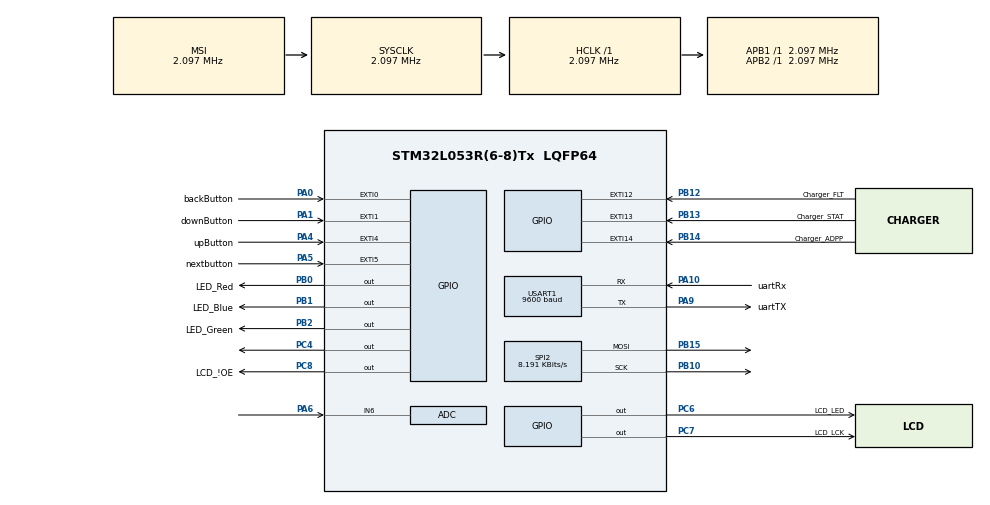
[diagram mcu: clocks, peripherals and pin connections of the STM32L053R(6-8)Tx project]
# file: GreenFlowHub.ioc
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ADC.ClockPrescaler=ADC_CLOCK_SYNC_PCLK_DIV4
ADC.ContinuousConvMode=ENABLE
ADC.Overrun=ADC_OVR_DATA_OVERWRITTEN
ADC.Resolution=ADC_RESOLUTION_12B
ADC.SamplingTime=ADC_SAMPLETIME_39CYCLES_5
Mcu.Family=STM32L0
Mcu.Name=STM32L053R(6-8)Tx
Mcu.Package=LQFP64
NVIC.EXTI0_1_IRQn=true\:0\:0\:false\:false\:true
NVIC.EXTI4_15_IRQn=true\:0\:0\:false\:false\:true
NVIC.USART1_IRQn=true\:0\:0\:false\:false\:true
PA0.GPIO_Label=backButton
PA0.GPIO_ModeDefaultEXTI=GPIO_MODE_IT_RISING
PA0.GPIO_PuPd=GPIO_PULLDOWN
PA0.Signal=GPXTI0
PA1.GPIO_Label=downButton
PA1.GPIO_PuPd=GPIO_PULLDOWN
PA1.Signal=GPXTI1
PA10.GPIO_Label=uartRx
PA10.GPIO_Speed=GPIO_SPEED_FREQ_VERY_HIGH
PA10.Mode=Asynchronous
PA10.Signal=USART1_RX
PA4.GPIO_Label=upButton
PA4.GPIO_PuPd=GPIO_PULLDOWN
PA4.Signal=GPXTI4
PA5.GPIO_Label=nextbutton
PA5.GPIO_PuPd=GPIO_PULLDOWN
PA5.Signal=GPXTI5
PA6.Mode=IN6
PA6.Signal=ADC_IN6
PA9.GPIO_Label=uartTX
PA9.GPIO_Speed=GPIO_SPEED_FREQ_VERY_HIGH
PA9.Mode=Asynchronous
PA9.Signal=USART1_TX
PB0.GPIO_Label=LED_Red
PB0.Signal=GPIO_Output
PB1.GPIO_Label=LED_Blue
PB1.Signal=GPIO_Output
PB10.Mode=TX_Only_Simplex_Unidirect_Master
PB10.Signal=SPI2_SCK
PB12.GPIO_Label=Charger_FLT
PB12.GPIO_PuPd=GPIO_PULLDOWN
PB12.Signal=GPXTI12
PB13.GPIO_Label=Charger_STAT
PB13.GPIO_PuPd=GPIO_PULLDOWN
PB13.Signal=GPXTI13
PB14.GPIO_Label=Charger_ADPP
PB14.GPIO_PuPd=GPIO_PULLDOWN
PB14.Signal=GPXTI14
PB15.Mode=TX_Only_Simplex_Unidirect_Master
PB15.Signal=SPI2_MOSI
PB2.GPIO_Label=LED_Green
PB2.Signal=GPIO_Output
PC4.Signal=GPIO_Output
PC6.GPIO_Label=LCD_LED
PC6.GPIO_PuPd=GPIO_PULLDOWN
PC6.Signal=GPIO_Output
PC7.GPIO_Label=LCD_LCK
PC7.GPIO_PuPd=GPIO_NOPULL
PC7.Signal=GPIO_Output
PC8.GPIO_Label=LCD_\!OE
PC8.GPIO_PuPd=GPIO_PULLDOWN
PC8.Signal=GPIO_Output
ProjectManager.HeapSize=0x200
ProjectManager.StackSize=0x400
ProjectManager.TargetToolchain=EWARM
RCC.AHBFreq_Value=2097000
RCC.APB1Freq_Value=2097000
RCC.APB1TimFreq_Value=2097000
RCC.APB2Freq_Value=2097000
RCC.APB2TimFreq_Value=2097000
RCC.HCLKFreq_Value=2097000
RCC.HSE_VALUE=8000000
RCC.HSI16_VALUE=16000000
RCC.HSI48_VALUE=48000000
RCC.HSI_VALUE=16000000
RCC.LSE_VALUE=32768
RCC.MSI_VALUE=2097000
RCC.SYSCLKFreq_VALUE=2097000
RCC.VCOOutputFreq_Value=48000000
SPI2.BaudRatePrescaler=SPI_BAUDRATEPRESCALER_256
SPI2.CalculateBaudRate=8.191 KBits/s
SPI2.Direction=SPI_DIRECTION_2LINES
SPI2.Mode=SPI_MODE_MASTER
SPI2.VirtualType=VM_MASTER
USART1.BaudRate=9600
USART1.VirtualMode-Asynchronous=VM_ASYNC
USART1.WordLength=WORDLENGTH_8B
board=GreenFlowHub

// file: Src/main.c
/**
  ******************************************************************************
  * File Name          : main.c
  * Description        : Main program body
  ******************************************************************************
  ** This notice applies to any and all portions of this file
  * that are not between comment pairs USER CODE BEGIN and
  * USER CODE END. Other portions of this file, whether
  * inserted by the user or by software development tools
  * are owned by their respective copyright owners.
  *
  * COPYRIGHT(c) 2017 STMicroelectronics
  *
  * Redistribution and use in source and binary forms, with or without modification,
  * are permitted provided that the following conditions are met:
  *   1. Redistributions of source code must retain the above copyright notice,
  *      this list of conditions and the following disclaimer.
  *   2. Redistributions in binary form must reproduce the above copyright notice,
  *      this list of conditions and the following disclaimer in the documentation
  *      and/or other materials provided with the distribution.
  *   3. Neither the name of STMicroelectronics nor the names of its contributors
  *      may be used to endorse or promote products derived from this software
  *      without specific prior written permission.
  *
  * THIS SOFTWARE IS PROVIDED BY THE COPYRIGHT HOLDERS AND CONTRIBUTORS "AS IS"
  * AND ANY EXPRESS OR IMPLIED WARRANTIES, INCLUDING, BUT NOT LIMITED TO, THE
  * IMPLIED WARRANTIES OF MERCHANTABILITY AND FITNESS FOR A PARTICULAR PURPOSE ARE
  * DISCLAIMED. IN NO EVENT SHALL THE COPYRIGHT HOLDER OR CONTRIBUTORS BE LIABLE
  * FOR ANY DIRECT, INDIRECT, INCIDENTAL, SPECIAL, EXEMPLARY, OR CONSEQUENTIAL
  * DAMAGES (INCLUDING, BUT NOT LIMITED TO, PROCUREMENT OF SUBSTITUTE GOODS OR
  * SERVICES; LOSS OF USE, DATA, OR PROFITS; OR BUSINESS INTERRUPTION) HOWEVER
  * CAUSED AND ON ANY THEORY OF LIABILITY, WHETHER IN CONTRACT, STRICT LIABILITY,
  * OR TORT (INCLUDING NEGLIGENCE OR OTHERWISE) ARISING IN ANY WAY OUT OF THE USE
  * OF THIS SOFTWARE, EVEN IF ADVISED OF THE POSSIBILITY OF SUCH DAMAGE.
  *
  ******************************************************************************
  */
#include "main.h"
#include "stm32l0xx_hal.h"

/* USER CODE BEGIN Includes */
#include "mainThread.h"
/* USER CODE END Includes */

ADC_HandleTypeDef hadc;

SPI_HandleTypeDef hspi2;

UART_HandleTypeDef huart1;

/* USER CODE BEGIN PV */
/* Private variables ---------------------------------------------------------*/

/* USER CODE END PV */

void SystemClock_Config(void);
static void MX_GPIO_Init(void);
static void MX_USART1_UART_Init(void);
static void MX_ADC_Init(void);
static void MX_SPI2_Init(void);

/* USER CODE BEGIN PFP */
/* Private function prototypes -----------------------------------------------*/

/* USER CODE END PFP */

int main(void)
{

  /* MCU Configuration----------------------------------------------------------*/

  /* Reset of all peripherals, Initializes the Flash interface and the Systick. */
  HAL_Init();

  /* Configure the system clock */
  SystemClock_Config();

  /* Initialize all configured peripherals */
  MX_GPIO_Init();
  MX_USART1_UART_Init();
  MX_ADC_Init();
  MX_SPI2_Init();

  /* USER CODE BEGIN 2 */
  int errorCode = 0;
  errorCode = initMainThread(&hadc, &huart1, &hspi2);
  /* USER CODE END 2 */

  /* Infinite loop */
  /* USER CODE BEGIN WHILE */
  while (1)
  {

    errorCode = mainThread(&hspi2);
    //fatal error has occured restart board
    if(errorCode)
    {
      //TODO: deal with fatal error with system reset
      while(1);
    }
  /* USER CODE END WHILE */

  }

}

/** System Clock Configuration
*/
void SystemClock_Config(void)
{

  RCC_OscInitTypeDef RCC_OscInitStruct;
  RCC_ClkInitTypeDef RCC_ClkInitStruct;
  RCC_PeriphCLKInitTypeDef PeriphClkInit;

    /**Configure the main internal regulator output voltage
    */
  __HAL_PWR_VOLTAGESCALING_CONFIG(PWR_REGULATOR_VOLTAGE_SCALE1);

    /**Initializes the CPU, AHB and APB busses clocks
    */
  RCC_OscInitStruct.OscillatorType = RCC_OSCILLATORTYPE_MSI;
  RCC_OscInitStruct.MSIState = RCC_MSI_ON;
  RCC_OscInitStruct.MSICalibrationValue = 0;
  RCC_OscInitStruct.MSIClockRange = RCC_MSIRANGE_5;
  RCC_OscInitStruct.PLL.PLLState = RCC_PLL_NONE;
  if (HAL_RCC_OscConfig(&RCC_OscInitStruct) != HAL_OK)
  {
    _Error_Handler(__FILE__, __LINE__);
  }

    /**Initializes the CPU, AHB and APB busses clocks
    */
  RCC_ClkInitStruct.ClockType = RCC_CLOCKTYPE_HCLK|RCC_CLOCKTYPE_SYSCLK
                              |RCC_CLOCKTYPE_PCLK1|RCC_CLOCKTYPE_PCLK2;
  RCC_ClkInitStruct.SYSCLKSource = RCC_SYSCLKSOURCE_MSI;
  RCC_ClkInitStruct.AHBCLKDivider = RCC_SYSCLK_DIV1;
  RCC_ClkInitStruct.APB1CLKDivider = RCC_HCLK_DIV1;
  RCC_ClkInitStruct.APB2CLKDivider = RCC_HCLK_DIV1;

  if (HAL_RCC_ClockConfig(&RCC_ClkInitStruct, FLASH_LATENCY_0) != HAL_OK)
  {
    _Error_Handler(__FILE__, __LINE__);
  }

  PeriphClkInit.PeriphClockSelection = RCC_PERIPHCLK_USART1;
  PeriphClkInit.Usart1ClockSelection = RCC_USART1CLKSOURCE_PCLK2;
  if (HAL_RCCEx_PeriphCLKConfig(&PeriphClkInit) != HAL_OK)
  {
    _Error_Handler(__FILE__, __LINE__);
  }

    /**Configure the Systick interrupt time
    */
  HAL_SYSTICK_Config(HAL_RCC_GetHCLKFreq()/1000);

    /**Configure the Systick
    */
  HAL_SYSTICK_CLKSourceConfig(SYSTICK_CLKSOURCE_HCLK);

  /* SysTick_IRQn interrupt configuration */
  HAL_NVIC_SetPriority(SysTick_IRQn, 0, 0);
}

/* ADC init function */
static void MX_ADC_Init(void)
{

  ADC_ChannelConfTypeDef sConfig;

    /**Configure the global features of the ADC (Clock, Resolution, Data Alignment and number of conversion)
    */
  hadc.Instance = ADC1;
  hadc.Init.OversamplingMode = DISABLE;
  hadc.Init.ClockPrescaler = ADC_CLOCK_SYNC_PCLK_DIV4;
  hadc.Init.Resolution = ADC_RESOLUTION_12B;
  hadc.Init.SamplingTime = ADC_SAMPLETIME_39CYCLES_5;
  hadc.Init.ScanConvMode = ADC_SCAN_DIRECTION_FORWARD;
  hadc.Init.DataAlign = ADC_DATAALIGN_RIGHT;
  hadc.Init.ContinuousConvMode = ENABLE;
  hadc.Init.DiscontinuousConvMode = DISABLE;
  hadc.Init.ExternalTrigConvEdge = ADC_EXTERNALTRIGCONVEDGE_NONE;
  hadc.Init.ExternalTrigConv = ADC_SOFTWARE_START;
  hadc.Init.DMAContinuousRequests = DISABLE;
  hadc.Init.EOCSelection = ADC_EOC_SINGLE_CONV;
  hadc.Init.Overrun = ADC_OVR_DATA_OVERWRITTEN;
  hadc.Init.LowPowerAutoWait = DISABLE;
  hadc.Init.LowPowerFrequencyMode = DISABLE;
  hadc.Init.LowPowerAutoPowerOff = DISABLE;
  if (HAL_ADC_Init(&hadc) != HAL_OK)
  {
    _Error_Handler(__FILE__, __LINE__);
  }

    /**Configure for the selected ADC regular channel to be converted.
    */
  sConfig.Channel = ADC_CHANNEL_6;
  sConfig.Rank = ADC_RANK_CHANNEL_NUMBER;
  if (HAL_ADC_ConfigChannel(&hadc, &sConfig) != HAL_OK)
  {
    _Error_Handler(__FILE__, __LINE__);
  }

}

/* SPI2 init function */
static void MX_SPI2_Init(void)
{

  hspi2.Instance = SPI2;
  hspi2.Init.Mode = SPI_MODE_MASTER;
  hspi2.Init.Direction = SPI_DIRECTION_2LINES;
  hspi2.Init.DataSize = SPI_DATASIZE_8BIT;
  hspi2.Init.CLKPolarity = SPI_POLARITY_LOW;
  hspi2.Init.CLKPhase = SPI_PHASE_1EDGE;
  hspi2.Init.NSS = SPI_NSS_SOFT;
  hspi2.Init.BaudRatePrescaler = SPI_BAUDRATEPRESCALER_256;
  hspi2.Init.FirstBit = SPI_FIRSTBIT_MSB;
  hspi2.Init.TIMode = SPI_TIMODE_DISABLE;
  hspi2.Init.CRCCalculation = SPI_CRCCALCULATION_DISABLE;
  hspi2.Init.CRCPolynomial = 7;
  if (HAL_SPI_Init(&hspi2) != HAL_OK)
  {
    _Error_Handler(__FILE__, __LINE__);
  }

}

/* USART1 init function */
static void MX_USART1_UART_Init(void)
{

  huart1.Instance = USART1;
  huart1.Init.BaudRate = 9600;
  huart1.Init.WordLength = UART_WORDLENGTH_8B;
  huart1.Init.StopBits = UART_STOPBITS_1;
  huart1.Init.Parity = UART_PARITY_NONE;
  huart1.Init.Mode = UART_MODE_TX_RX;
  huart1.Init.HwFlowCtl = UART_HWCONTROL_NONE;
  huart1.Init.OverSampling = UART_OVERSAMPLING_16;
  huart1.Init.OneBitSampling = UART_ONE_BIT_SAMPLE_DISABLE;
  huart1.AdvancedInit.AdvFeatureInit = UART_ADVFEATURE_NO_INIT;
  if (HAL_UART_Init(&huart1) != HAL_OK)
  {
    _Error_Handler(__FILE__, __LINE__);
  }

}

/** Configure pins as
        * Analog
        * Input
        * Output
        * EVENT_OUT
        * EXTI
*/
static void MX_GPIO_Init(void)
{

  GPIO_InitTypeDef GPIO_InitStruct;

  /* GPIO Ports Clock Enable */
  __HAL_RCC_GPIOA_CLK_ENABLE();
  __HAL_RCC_GPIOC_CLK_ENABLE();
  __HAL_RCC_GPIOB_CLK_ENABLE();

  /*Configure GPIO pin Output Level */
  HAL_GPIO_WritePin(GPIOC, GPIO_PIN_4|LCD_LED_Pin|LCD_LCK_Pin|LCD__OE_Pin, GPIO_PIN_RESET);

  /*Configure GPIO pin Output Level */
  HAL_GPIO_WritePin(GPIOB, LED_Red_Pin|LED_Blue_Pin|LED_Green_Pin, GPIO_PIN_RESET);

  /*Configure GPIO pins : backButton_Pin downButton_Pin upButton_Pin nextbutton_Pin */
  GPIO_InitStruct.Pin = backButton_Pin|downButton_Pin|upButton_Pin|nextbutton_Pin;
  GPIO_InitStruct.Mode = GPIO_MODE_IT_RISING;
  GPIO_InitStruct.Pull = GPIO_PULLDOWN;
  HAL_GPIO_Init(GPIOA, &GPIO_InitStruct);

  /*Configure GPIO pins : PC4 LCD_LCK_Pin */
  GPIO_InitStruct.Pin = GPIO_PIN_4|LCD_LCK_Pin;
  GPIO_InitStruct.Mode = GPIO_MODE_OUTPUT_PP;
  GPIO_InitStruct.Pull = GPIO_NOPULL;
  GPIO_InitStruct.Speed = GPIO_SPEED_FREQ_LOW;
  HAL_GPIO_Init(GPIOC, &GPIO_InitStruct);

  /*Configure GPIO pins : LED_Red_Pin LED_Blue_Pin LED_Green_Pin */
  GPIO_InitStruct.Pin = LED_Red_Pin|LED_Blue_Pin|LED_Green_Pin;
  GPIO_InitStruct.Mode = GPIO_MODE_OUTPUT_PP;
  GPIO_InitStruct.Pull = GPIO_NOPULL;
  GPIO_InitStruct.Speed = GPIO_SPEED_FREQ_LOW;
  HAL_GPIO_Init(GPIOB, &GPIO_InitStruct);

  /*Configure GPIO pins : Charger_FLT_Pin Charger_STAT_Pin Charger_ADPP_Pin */
  GPIO_InitStruct.Pin = Charger_FLT_Pin|Charger_STAT_Pin|Charger_ADPP_Pin;
  GPIO_InitStruct.Mode = GPIO_MODE_IT_RISING;
  GPIO_InitStruct.Pull = GPIO_PULLDOWN;
  HAL_GPIO_Init(GPIOB, &GPIO_InitStruct);

  /*Configure GPIO pins : LCD_LED_Pin LCD__OE_Pin */
  GPIO_InitStruct.Pin = LCD_LED_Pin|LCD__OE_Pin;
  GPIO_InitStruct.Mode = GPIO_MODE_OUTPUT_PP;
  GPIO_InitStruct.Pull = GPIO_PULLDOWN;
  GPIO_InitStruct.Speed = GPIO_SPEED_FREQ_LOW;
  HAL_GPIO_Init(GPIOC, &GPIO_InitStruct);

  /* EXTI interrupt init*/
  HAL_NVIC_SetPriority(EXTI0_1_IRQn, 0, 0);
  HAL_NVIC_EnableIRQ(EXTI0_1_IRQn);

  HAL_NVIC_SetPriority(EXTI4_15_IRQn, 0, 0);
  HAL_NVIC_EnableIRQ(EXTI4_15_IRQn);

}

void _Error_Handler(char * file, int line)
{
  while(1)
  {
  }
}

/************************ (C) COPYRIGHT STMicroelectronics *****END OF FILE****/
